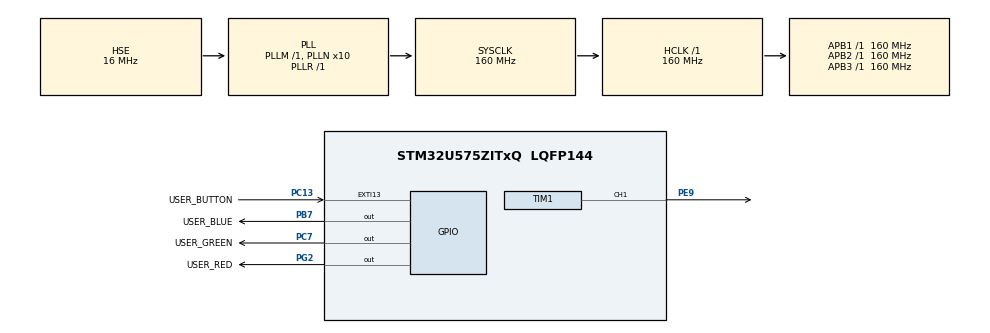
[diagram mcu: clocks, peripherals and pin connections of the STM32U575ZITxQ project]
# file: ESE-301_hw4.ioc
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CORTEX_M33_NS.userName=CORTEX_M33
Mcu.Family=STM32U5
Mcu.Name=STM32U575ZITxQ
Mcu.Package=LQFP144
NVIC.EXTI13_IRQn=true\:0\:0\:false\:false\:true\:true\:true\:true
NVIC.PriorityGroup=NVIC_PRIORITYGROUP_3
NVIC.TIM17_IRQn=true\:7\:0\:false\:false\:true\:false\:true\:true
NVIC.TimeBase=TIM17_IRQn
NVIC.TimeBaseIP=TIM17
PA10.Signal=USART1_RX
PA13\ (JTMS/SWDIO).Signal=DEBUG_JTMS-SWDIO
PA14\ (JTCK/SWCLK).Signal=DEBUG_JTCK-SWCLK
PA9.Signal=USART1_TX
PB3\ (JTDO/TRACESWO).Signal=DEBUG_JTDO-SWO
PB7.GPIO_Label=USER_BLUE
PB7.Signal=GPIO_Output
PC13.GPIO_Label=USER_BUTTON
PC13.GPIO_PuPd=GPIO_NOPULL
PC13.Signal=GPXTI13
PC14-OSC32_IN\ (PC14).Mode=LSE-External-Oscillator
PC14-OSC32_IN\ (PC14).Signal=RCC_OSC32_IN
PC15-OSC32_OUT\ (PC15).Mode=LSE-External-Oscillator
PC15-OSC32_OUT\ (PC15).Signal=RCC_OSC32_OUT
PC7.GPIO_Label=USER_GREEN
PC7.Signal=GPIO_Output
PE9.Signal=S_TIM1_CH1
PG2.GPIO_Label=USER_RED
PG2.Signal=GPIO_Output
PH0-OSC_IN\ (PH0).Mode=HSE-External-Oscillator
PH0-OSC_IN\ (PH0).Signal=RCC_OSC_IN
PH1-OSC_OUT\ (PH1).Mode=HSE-External-Oscillator
PH1-OSC_OUT\ (PH1).Signal=RCC_OSC_OUT
PWR.PowerMode=PWR_SMPS_SUPPLY
ProjectManager.HeapSize=0x200
ProjectManager.StackSize=0x400
ProjectManager.TargetToolchain=CMake
RCC.ADCFreq_Value=16000000
RCC.AHBFreq_Value=160000000
RCC.APB1Freq_Value=160000000
RCC.APB1TimFreq_Value=160000000
RCC.APB2Freq_Value=160000000
RCC.APB2TimFreq_Value=160000000
RCC.APB3Freq_Value=160000000
RCC.CortexFreq_Value=160000000
RCC.DACCLockSelectionVirtual=RCC_DAC1CLKSOURCE_LSI
RCC.EPOD_VALUE=16000000
RCC.HCLKFreq_Value=160000000
RCC.HSE_VALUE=16000000
RCC.HSI48_VALUE=48000000
RCC.HSI_VALUE=16000000
RCC.LSIDIV_VALUE=32000
RCC.MSI_VALUE=4000000
RCC.PLL1R=1
RCC.PLL2FRACN=0
RCC.PLL3FRACN=0
RCC.PLLFRACN=0
RCC.PLLN=10
RCC.PLLSourceVirtual=RCC_PLLSOURCE_HSE
RCC.SYSCLKFreq_VALUE=160000000
RCC.SYSCLKSource=RCC_SYSCLKSOURCE_PLLCLK
RCC.USBFreq_Value=48000000
RCC.VCOOutputFreq_Value=160000000
SH.S_TIM1_CH1.0=TIM1_CH1,PWM Generation1 CH1
TIM1.Channel-PWM\ Generation1\ CH1=TIM_CHANNEL_1
TIM1.PeriodNoDither=1000-1
TIM1.Prescaler=160-1
VP_ICACHE_VS_ENABLE_ICACHE_MEMORY.Mode=Memoryregions
VP_ICACHE_VS_ICACHE.Mode=DirectMappedCache
VP_LPBAMQUEUE_VS_QUEUE.Mode=QUEUEMODE
VP_LPBAM_VS_SIG1.Mode=SmartRun
VP_LPBAM_VS_SIG4.Mode=LPDMA1
VP_MEMORYMAP_VS_MEMORYMAP.Mode=CurAppReg
VP_PWR_VS_DBSignals.Mode=DisableDeadBatterySignals
VP_PWR_VS_LPOM.Mode=PowerOptimisation
VP_PWR_VS_SECSignals.Mode=Security/Privilege
VP_SYS_VS_tim17.Mode=TIM17
board=NUCLEO-U575ZI-Q

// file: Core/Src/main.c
/* USER CODE BEGIN Header */
/**
  ******************************************************************************
  * @file           : main.c
  * @brief          : Main program body
  ******************************************************************************
  * @attention
  *
  * Copyright (c) 2026 STMicroelectronics.
  * All rights reserved.
  *
  * This software is licensed under terms that can be found in the LICENSE file
  * in the root directory of this software component.
  * If no LICENSE file comes with this software, it is provided AS-IS.
  *
  ******************************************************************************
  */
/* USER CODE END Header */
#include "main.h"
#include "icache.h"
#include "tim.h"
#include "gpio.h"

/* USER CODE BEGIN Includes */
#include "led.h"
#include "button.h"
/* USER CODE END Includes */

void SystemClock_Config(void);
static void SystemPower_Config(void);

int main(void)
{

  /* MCU Configuration--------------------------------------------------------*/

  /* Reset of all peripherals, Initializes the Flash interface and the Systick. */
  HAL_Init();

  /* Configure the System Power */
  SystemPower_Config();

  /* Configure the system clock */
  SystemClock_Config();

  /* Initialize all configured peripherals */
  MX_GPIO_Init();
  MX_ICACHE_Init();
  MX_TIM1_Init();
  /* USER CODE BEGIN 2 */
  BUTTON_Init();
  LED_Off(LED_BLUE);
  /* USER CODE END 2 */

  /* Infinite loop */
  while (1)
  {

    /* USER CODE BEGIN 3 */
    if (BUTTON_GetState() == BUTTON_PRESSED)
    {
      LED_On(LED_BLUE);
    }
    else
    {
      LED_Off(LED_BLUE);
    }

    HAL_Delay(10);
  }
  /* USER CODE END 3 */
}

void SystemClock_Config(void)
{
  uint8_t use_hsi_fallback = 0U;
  RCC_OscInitTypeDef RCC_OscInitStruct = {0};
  RCC_ClkInitTypeDef RCC_ClkInitStruct = {0};

  /** Configure the main internal regulator output voltage
  */
  if (HAL_PWREx_ControlVoltageScaling(PWR_REGULATOR_VOLTAGE_SCALE1) != HAL_OK)
  {
    Error_Handler();
  }

  /** Initializes the CPU, AHB and APB buses clocks
  */
  RCC_OscInitStruct.OscillatorType = RCC_OSCILLATORTYPE_HSE;
  RCC_OscInitStruct.HSEState = RCC_HSE_ON;
  RCC_OscInitStruct.PLL.PLLState = RCC_PLL_ON;
  RCC_OscInitStruct.PLL.PLLSource = RCC_PLLSOURCE_HSE;
  RCC_OscInitStruct.PLL.PLLMBOOST = RCC_PLLMBOOST_DIV1;
  RCC_OscInitStruct.PLL.PLLM = 1;
  RCC_OscInitStruct.PLL.PLLN = 10;
  RCC_OscInitStruct.PLL.PLLP = 2;
  RCC_OscInitStruct.PLL.PLLQ = 2;
  RCC_OscInitStruct.PLL.PLLR = 1;
  RCC_OscInitStruct.PLL.PLLRGE = RCC_PLLVCIRANGE_1;
  RCC_OscInitStruct.PLL.PLLFRACN = 0;
  if (HAL_RCC_OscConfig(&RCC_OscInitStruct) != HAL_OK)
  {
    use_hsi_fallback = 1U;
  }

  if (use_hsi_fallback == 0U)
  {
    /** Initializes the CPU, AHB and APB buses clocks
    */
    RCC_ClkInitStruct.ClockType = RCC_CLOCKTYPE_HCLK|RCC_CLOCKTYPE_SYSCLK
                                |RCC_CLOCKTYPE_PCLK1|RCC_CLOCKTYPE_PCLK2
                                |RCC_CLOCKTYPE_PCLK3;
    RCC_ClkInitStruct.SYSCLKSource = RCC_SYSCLKSOURCE_PLLCLK;
    RCC_ClkInitStruct.AHBCLKDivider = RCC_SYSCLK_DIV1;
    RCC_ClkInitStruct.APB1CLKDivider = RCC_HCLK_DIV1;
    RCC_ClkInitStruct.APB2CLKDivider = RCC_HCLK_DIV1;
    RCC_ClkInitStruct.APB3CLKDivider = RCC_HCLK_DIV1;

    if (HAL_RCC_ClockConfig(&RCC_ClkInitStruct, FLASH_LATENCY_4) != HAL_OK)
    {
      use_hsi_fallback = 1U;
    }
  }

  if (use_hsi_fallback != 0U)
  {
    RCC_OscInitStruct.OscillatorType = RCC_OSCILLATORTYPE_HSI;
    RCC_OscInitStruct.HSEState = RCC_HSE_OFF;
    RCC_OscInitStruct.HSIState = RCC_HSI_ON;
    RCC_OscInitStruct.PLL.PLLState = RCC_PLL_OFF;

    if (HAL_RCC_OscConfig(&RCC_OscInitStruct) != HAL_OK)
    {
      Error_Handler();
    }

    RCC_ClkInitStruct.ClockType = RCC_CLOCKTYPE_HCLK|RCC_CLOCKTYPE_SYSCLK
                                |RCC_CLOCKTYPE_PCLK1|RCC_CLOCKTYPE_PCLK2
                                |RCC_CLOCKTYPE_PCLK3;
    RCC_ClkInitStruct.SYSCLKSource = RCC_SYSCLKSOURCE_HSI;
    RCC_ClkInitStruct.AHBCLKDivider = RCC_SYSCLK_DIV1;
    RCC_ClkInitStruct.APB1CLKDivider = RCC_HCLK_DIV1;
    RCC_ClkInitStruct.APB2CLKDivider = RCC_HCLK_DIV1;
    RCC_ClkInitStruct.APB3CLKDivider = RCC_HCLK_DIV1;

    if (HAL_RCC_ClockConfig(&RCC_ClkInitStruct, FLASH_LATENCY_0) != HAL_OK)
    {
      Error_Handler();
    }
  }
}

/**
  * @brief Power Configuration
  * @retval None
  */
static void SystemPower_Config(void)
{
  HAL_PWREx_EnableVddIO2();

  /*
   * Disable the internal Pull-Up in Dead Battery pins of UCPD peripheral
   */
  HAL_PWREx_DisableUCPDDeadBattery();

  /*
   * Switch to SMPS regulator instead of LDO
   */
  if (HAL_PWREx_ConfigSupply(PWR_SMPS_SUPPLY) != HAL_OK)
  {
    Error_Handler();
  }
}

void HAL_TIM_PeriodElapsedCallback(TIM_HandleTypeDef *htim)
{
  if (htim->Instance == TIM17)
  {
    HAL_IncTick();
  }
}

void Error_Handler(void)
{
  __disable_irq();
  while (1)
  {
  }
}
